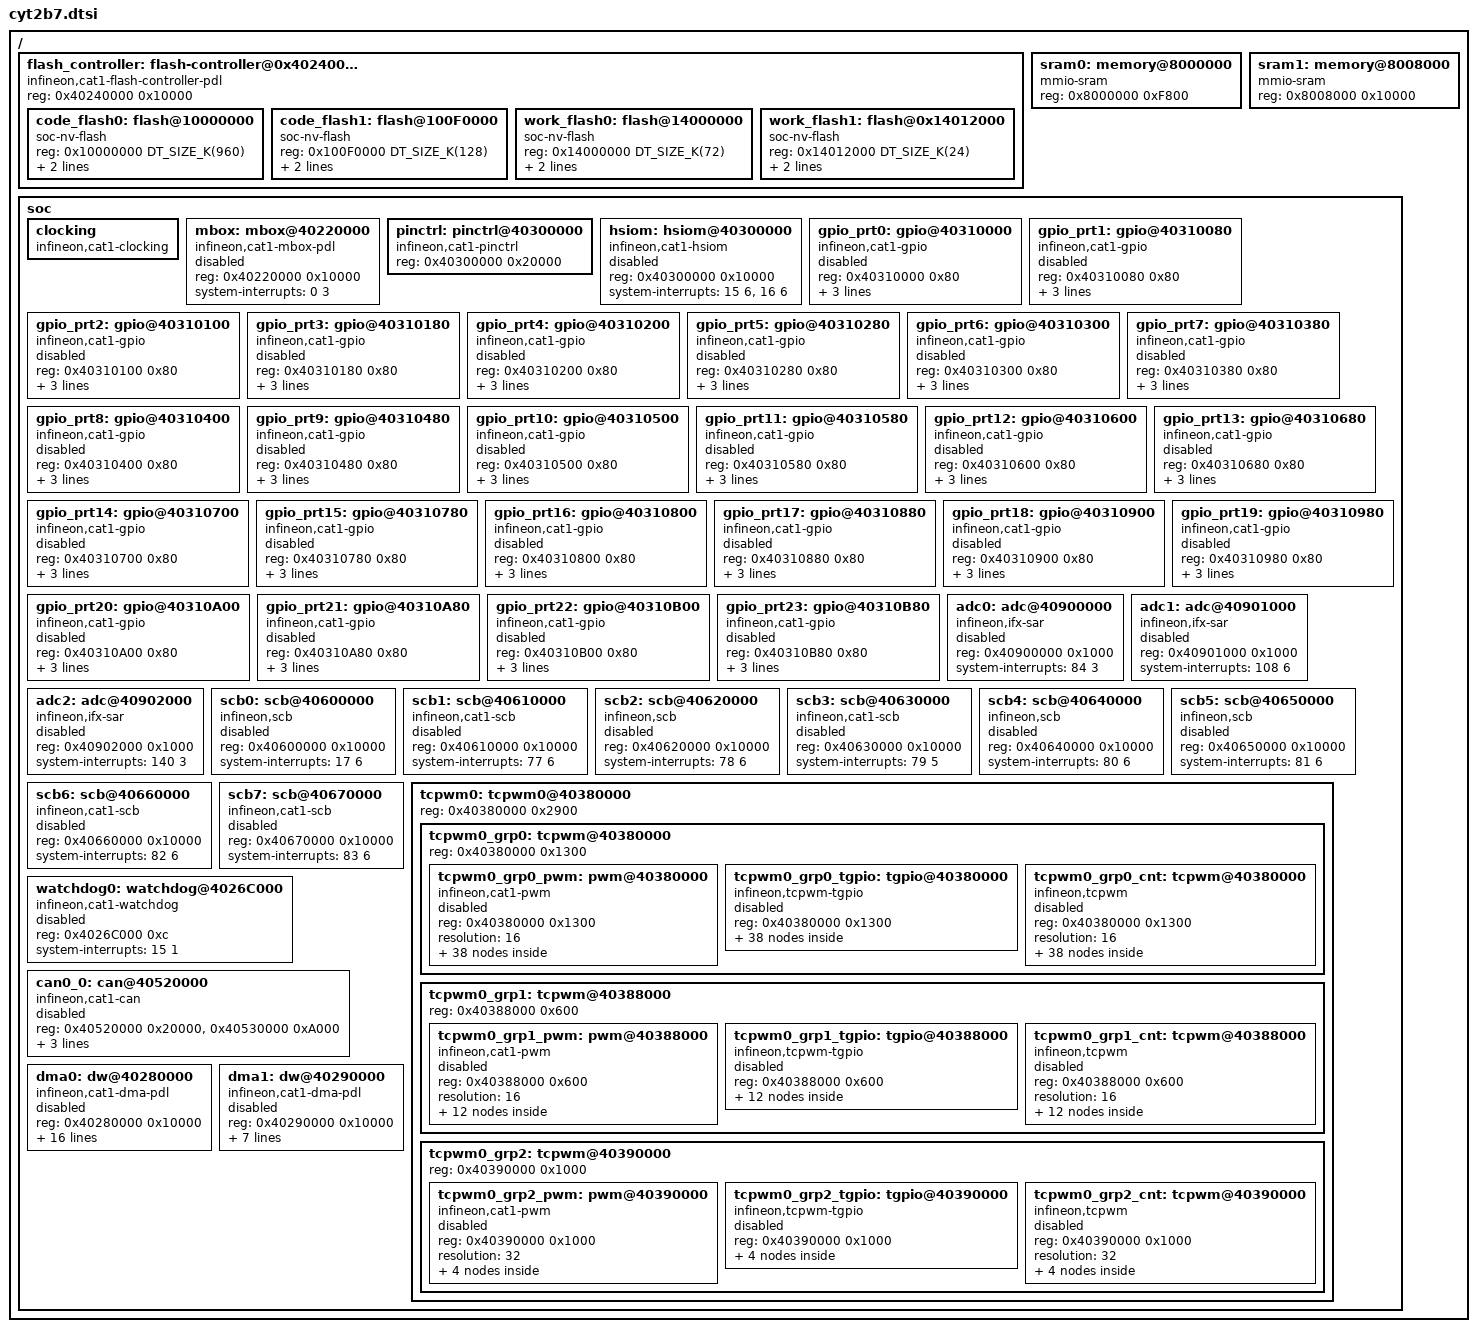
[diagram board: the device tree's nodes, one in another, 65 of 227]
/*
 * Copyright (c) 2025 Infineon Technologies AG,
 * or an affiliate of Infineon Technologies AG.
 *
 * SPDX-License-Identifier: Apache-2.0
 */

#include <mem.h>

/ {

	flash_controller: flash-controller@0x40240000 {
		compatible = "infineon,cat1-flash-controller-pdl";
		reg = <0x40240000 0x10000>;
		#address-cells = <1>;
		#size-cells = <1>;
		status = "okay";


		/* Code flash - Large sector (32KB Sectors) */
		code_flash0: flash@10000000 {
			compatible = "soc-nv-flash";
			reg = <0x10000000 DT_SIZE_K(960)>;
			write-block-size = <512>;
			erase-block-size = <32768>;
		};

		/* Code flash - Small sector (8KB Sectors) */
		code_flash1: flash@100F0000 {
			compatible = "soc-nv-flash";
			reg = <0x100F0000 DT_SIZE_K(128)>;
			write-block-size = <512>;
			erase-block-size = <8192>;
		};
		/* Work flash - Large sector (2KB Sectors) */
		work_flash0: flash@14000000 {
			compatible = "soc-nv-flash";
			reg = <0x14000000 DT_SIZE_K(72)>;
			write-block-size = <512>;
			erase-block-size = <2048>;
		};

		/* Work flash - Small sector (128B Sectors) */
		work_flash1: flash@0x14012000 {
			compatible = "soc-nv-flash";
			reg = <0x14012000 DT_SIZE_K(24)>;
			write-block-size = <64>;
			erase-block-size = <128>;
		};

	};

    sram0: memory@8000000 {
		compatible = "mmio-sram";
		reg = <0x8000000 0xF800>;
	};

	sram1: memory@8008000 {
		compatible = "mmio-sram";
		reg = <0x8008000 0x10000>;
	};


    soc {

		#address-cells = <1>;
		#size-cells = <1>;

		clocking: clocking {
			compatible = "infineon,cat1-clocking";
		};

		mbox: mbox@40220000 {
            compatible = "infineon,cat1-mbox-pdl";
            reg = <0x40220000 0x10000>;
            system-interrupts = <0 3>;
            #mbox-cells = <1>;
            status = "disabled";
        };

		pinctrl: pinctrl@40300000 {
			compatible = "infineon,cat1-pinctrl";
			reg = <0x40300000 0x20000>;
			#address-cells = <1>;
			#size-cells = <0>;
		};

		hsiom: hsiom@40300000 {
			compatible = "infineon,cat1-hsiom";
			reg = <0x40300000 0x10000>;
			system-interrupts = <15 6>, <16 6>;
			status = "disabled";
		};

        gpio_prt0: gpio@40310000 {
			compatible = "infineon,cat1-gpio";
			reg = <0x40310000 0x80>;
			system-interrupts = <21 6>;
			gpio-controller;
			ngpios = <8>;
			status = "disabled";
			#gpio-cells = <2>;
		};

        gpio_prt1: gpio@40310080 {
			compatible = "infineon,cat1-gpio";
			reg = <0x40310080 0x80>;
			system-interrupts = <22 6>;
			gpio-controller;
			ngpios = <8>;
			status = "disabled";
			#gpio-cells = <2>;
		};

        gpio_prt2: gpio@40310100 {
			compatible = "infineon,cat1-gpio";
			reg = <0x40310100 0x80>;
			system-interrupts = <23 6>;
			gpio-controller;
			ngpios = <8>;
			status = "disabled";
			#gpio-cells = <2>;
		};

        gpio_prt3: gpio@40310180 {
			compatible = "infineon,cat1-gpio";
			reg = <0x40310180 0x80>;
			system-interrupts = <24 6>;
			gpio-controller;
			ngpios = <8>;
			status = "disabled";
			#gpio-cells = <2>;
		};

        gpio_prt4: gpio@40310200 {
			compatible = "infineon,cat1-gpio";
			reg = <0x40310200 0x80>;
			system-interrupts = <25 6>;
			gpio-controller;
			ngpios = <8>;
			status = "disabled";
			#gpio-cells = <2>;
		};

        gpio_prt5: gpio@40310280 {
			compatible = "infineon,cat1-gpio";
			reg = <0x40310280 0x80>;
			system-interrupts = <26 6>;
			gpio-controller;
			ngpios = <8>;
			status = "disabled";
			#gpio-cells = <2>;
		};

        gpio_prt6: gpio@40310300 {
			compatible = "infineon,cat1-gpio";
			reg = <0x40310300 0x80>;
			system-interrupts = <27 6>;
			gpio-controller;
			ngpios = <8>;
			status = "disabled";
			#gpio-cells = <2>;
		};

        gpio_prt7: gpio@40310380 {
			compatible = "infineon,cat1-gpio";
			reg = <0x40310380 0x80>;
			system-interrupts = <28 6>;
			gpio-controller;
			ngpios = <8>;
			status = "disabled";
			#gpio-cells = <2>;
		};

        gpio_prt8: gpio@40310400 {
			compatible = "infineon,cat1-gpio";
			reg = <0x40310400 0x80>;
			system-interrupts = <29 6>;
			gpio-controller;
			ngpios = <8>;
			status = "disabled";
			#gpio-cells = <2>;
		};

        gpio_prt9: gpio@40310480 {
			compatible = "infineon,cat1-gpio";
			reg = <0x40310480 0x80>;
			system-interrupts = <30 6>;
			gpio-controller;
			ngpios = <8>;
			status = "disabled";
			#gpio-cells = <2>;
		};

        gpio_prt10: gpio@40310500 {
			compatible = "infineon,cat1-gpio";
			reg = <0x40310500 0x80>;
			system-interrupts = <31 6>;
			gpio-controller;
			ngpios = <8>;
			status = "disabled";
			#gpio-cells = <2>;
		};

        gpio_prt11: gpio@40310580 {
			compatible = "infineon,cat1-gpio";
			reg = <0x40310580 0x80>;
			system-interrupts = <32 6>;
			gpio-controller;
			ngpios = <8>;
			status = "disabled";
			#gpio-cells = <2>;
		};


        gpio_prt12: gpio@40310600 {
			compatible = "infineon,cat1-gpio";
			reg = <0x40310600 0x80>;
			system-interrupts = <33 6>;
			gpio-controller;
			ngpios = <8>;
			status = "disabled";
			#gpio-cells = <2>;
		};

        gpio_prt13: gpio@40310680 {
			compatible = "infineon,cat1-gpio";
			reg = <0x40310680 0x80>;
			system-interrupts = <34 6>;
			gpio-controller;
			ngpios = <8>;
			status = "disabled";
			#gpio-cells = <2>;
		};

        gpio_prt14: gpio@40310700 {
			compatible = "infineon,cat1-gpio";
			reg = <0x40310700 0x80>;
			system-interrupts = <35 6>;
			gpio-controller;
			ngpios = <8>;
			status = "disabled";
			#gpio-cells = <2>;
		};

        gpio_prt15: gpio@40310780 {
			compatible = "infineon,cat1-gpio";
			reg = <0x40310780 0x80>;
			system-interrupts = <36 6>;
			gpio-controller;
			ngpios = <8>;
			status = "disabled";
			#gpio-cells = <2>;
		};

        gpio_prt16: gpio@40310800 {
			compatible = "infineon,cat1-gpio";
			reg = <0x40310800 0x80>;
			system-interrupts = <37 6>;
			gpio-controller;
			ngpios = <8>;
			status = "disabled";
			#gpio-cells = <2>;
		};

        gpio_prt17: gpio@40310880 {
			compatible = "infineon,cat1-gpio";
			reg = <0x40310880 0x80>;
			system-interrupts = <38 6>;
			gpio-controller;
			ngpios = <8>;
			status = "disabled";
			#gpio-cells = <2>;
		};

        gpio_prt18: gpio@40310900 {
			compatible = "infineon,cat1-gpio";
			reg = <0x40310900 0x80>;
			system-interrupts = <39 6>;
			gpio-controller;
			ngpios = <8>;
			status = "disabled";
			#gpio-cells = <2>;
		};

        gpio_prt19: gpio@40310980 {
			compatible = "infineon,cat1-gpio";
			reg = <0x40310980 0x80>;
			system-interrupts = <40 6>;
			gpio-controller;
			ngpios = <8>;
			status = "disabled";
			#gpio-cells = <2>;
		};

        gpio_prt20: gpio@40310A00 {
			compatible = "infineon,cat1-gpio";
			reg = <0x40310A00 0x80>;
			system-interrupts = <41 6>;
			gpio-controller;
			ngpios = <8>;
			status = "disabled";
			#gpio-cells = <2>;
		};

        gpio_prt21: gpio@40310A80 {
			compatible = "infineon,cat1-gpio";
			reg = <0x40310A80 0x80>;
			system-interrupts = <42 6>;
			gpio-controller;
			ngpios = <8>;
			status = "disabled";
			#gpio-cells = <2>;
		};

        gpio_prt22: gpio@40310B00 {
			compatible = "infineon,cat1-gpio";
			reg = <0x40310B00 0x80>;
			system-interrupts = <43 6>;
			gpio-controller;
			ngpios = <8>;
			status = "disabled";
			#gpio-cells = <2>;
		};

        gpio_prt23: gpio@40310B80 {
			compatible = "infineon,cat1-gpio";
			reg = <0x40310B80 0x80>;
			system-interrupts = <44 6>;
			gpio-controller;
			ngpios = <8>;
			status = "disabled";
			#gpio-cells = <2>;
		};

		adc0: adc@40900000 {
			compatible = "infineon,ifx-sar";
			reg = <0x40900000 0x1000>;
			system-interrupts = <84 3>;
			status = "disabled";
			#io-channel-cells = <1>;

		};

		adc1: adc@40901000 {
			compatible = "infineon,ifx-sar";
			reg = <0x40901000 0x1000>;
			system-interrupts = <108 6>;
			status = "disabled";
			#io-channel-cells = <1>;
		};

		adc2: adc@40902000 {
			compatible = "infineon,ifx-sar";
			reg = <0x40902000 0x1000>;
			system-interrupts = <140 3>;
			status = "disabled";
			#io-channel-cells = <1>;
		};


		scb0: scb@40600000 {
			compatible = "infineon,scb";
			reg = <0x40600000 0x10000>;
			#address-cells = <1>;
			#size-cells = <0>;
			system-interrupts = <17 6>;
			status = "disabled";
		};

		scb1: scb@40610000 {
			compatible = "infineon,cat1-scb";
			reg = <0x40610000 0x10000>;
			#address-cells = <1>;
			#size-cells = <0>;
			system-interrupts = <77 6>;
			status = "disabled";
		};

		scb2: scb@40620000 {
			compatible = "infineon,scb";
			reg = <0x40620000 0x10000>;
			#address-cells = <1>;
			#size-cells = <0>;
			system-interrupts = <78 6>;
			status = "disabled";
		};

		scb3: scb@40630000 {
			compatible = "infineon,cat1-scb";
			reg = <0x40630000 0x10000>;
			#address-cells = <1>;
			#size-cells = <0>;
			system-interrupts = <79 5>;
			status = "disabled";
		};

		scb4: scb@40640000 {
			compatible = "infineon,scb";
			reg = <0x40640000 0x10000>;
			#address-cells = <1>;
			#size-cells = <0>;
			system-interrupts = <80 6>;
			status = "disabled";
		};

		scb5: scb@40650000 {
			compatible = "infineon,scb";
			reg = <0x40650000 0x10000>;
			#address-cells = <1>;
			#size-cells = <0>;
			system-interrupts = <81 6>;
			status = "disabled";
		};

		scb6: scb@40660000 {
			compatible = "infineon,cat1-scb";
			reg = <0x40660000 0x10000>;
			#address-cells = <1>;
			#size-cells = <0>;
			system-interrupts = <82 6>;
			status = "disabled";
		};

		scb7: scb@40670000 {
			compatible = "infineon,cat1-scb";
			reg = <0x40670000 0x10000>;
			#address-cells = <1>;
			#size-cells = <0>;
			system-interrupts = <83 6>;
			status = "disabled";
		};

		 tcpwm0: tcpwm0@40380000 {
			reg = <0x40380000 0x2900>;
			#address-cells = <1>;
			#size-cells = <1>;
			tcpwm0_grp0: tcpwm@40380000 {
				reg = <0x40380000 0x1300>;
				#address-cells = <1>;
				#size-cells = <1>;
				tcpwm0_grp0_pwm: pwm@40380000 {
					compatible = "infineon,cat1-pwm";
					reg = <0x40380000 0x1300>;
					#address-cells = <1>;
					#size-cells = <0>;
					#pwm-cells = <3>;
					resolution = <16>;
					status = "disabled";

					pwm_ch0_0: channel@0 {
						reg = <0x0>;
						system-interrupts = <274 4>;
						status = "disabled";
					};

					pwm_ch0_1: channel@1 {
						reg = <0x1>;
						system-interrupts = <275 4>;
						status = "disabled";
					};

					pwm_ch0_2: channel@2 {
						reg = <0x2>;
						system-interrupts = <276 4>;
						status = "disabled";
					};

					pwm_ch0_3: channel@3 {
						reg = <0x3>;
						system-interrupts = <277 4>;
						status = "disabled";
					};

					pwm_ch0_4: channel@4 {
						reg = <0x4>;
						system-interrupts = <278 4>;
						status = "disabled";
					};

					pwm_ch0_5: channel@5 {
						reg = <0x5>;
						system-interrupts = <279 4>;
						status = "disabled";
					};

					pwm_ch0_6: channel@6 {
						reg = <0x6>;
						system-interrupts = <280 4>;
						status = "disabled";
					};

					pwm_ch0_7: channel@7 {
						reg = <0x7>;
						system-interrupts = <281 4>;
						status = "disabled";
					};

					pwm_ch0_8: channel@8 {
						reg = <0x8>;
						system-interrupts = <282 4>;
						status = "disabled";
					};

					pwm_ch0_9: channel@9 {
						reg = <0x9>;
						system-interrupts = <283 4>;
						status = "disabled";
					};

					pwm_ch0_10: channel@a {
						reg = <0xa>;
						system-interrupts = <284 4>;
						status = "disabled";
					};

					pwm_ch0_11: channel@b {
						reg = <0xb>;
						system-interrupts = <285 4>;
						status = "disabled";
					};

					pwm_ch0_12: channel@c {
						reg = <0xc>;
						system-interrupts = <286 4>;
						status = "disabled";
					};

					pwm_ch0_13: channel@d {
						reg = <0xd>;
						system-interrupts = <287 4>;
						status = "disabled";
					};

					pwm_ch0_14: channel@e {
						reg = <0xe>;
						system-interrupts = <288 4>;
						status = "disabled";
					};

					pwm_ch0_15: channel@f {
						reg = <0xf>;
						system-interrupts = <289 4>;
						status = "disabled";
					};

					pwm_ch0_16: channel@10 {
						reg = <0x10>;
						system-interrupts = <290 4>;
						status = "disabled";
					};

					pwm_ch0_17: channel@11 {
						reg = <0x11>;
						system-interrupts = <291 4>;
						status = "disabled";
					};

					pwm_ch0_18: channel@12 {
						reg = <0x12>;
						system-interrupts = <292 4>;
						status = "disabled";
					};

					pwm_ch0_19: channel@13 {
						reg = <0x13>;
						system-interrupts = <293 4>;
						status = "disabled";
					};

					pwm_ch0_20: channel@14 {
						reg = <0x14>;
						system-interrupts = <294 4>;
						status = "disabled";
					};

					pwm_ch0_21: channel@15 {
						reg = <0x15>;
						system-interrupts = <295 4>;
						status = "disabled";
					};

					pwm_ch0_22: channel@16 {
						reg = <0x16>;
						system-interrupts = <296 4>;
						status = "disabled";
					};

					pwm_ch0_23: channel@17 {
						reg = <0x17>;
						system-interrupts = <297 4>;
						status = "disabled";
					};

					pwm_ch0_24: channel@18 {
						reg = <0x18>;
						system-interrupts = <298 4>;
						status = "disabled";
					};

					pwm_ch0_25: channel@19 {
						reg = <0x19>;
						system-interrupts = <299 4>;
						status = "disabled";
					};

					pwm_ch0_26: channel@1a {
						reg = <0x1a>;
						system-interrupts = <300 4>;
						status = "disabled";
					};

					pwm_ch0_27: channel@1b {
						reg = <0x1b>;
						system-interrupts = <301 4>;
						status = "disabled";
					};

					pwm_ch0_28: channel@1c {
						reg = <0x1c>;
						system-interrupts = <302 4>;
						status = "disabled";
					};

					pwm_ch0_29: channel@1d {
						reg = <0x1d>;
						system-interrupts = <303 4>;
						status = "disabled";
					};

					pwm_ch0_30: channel@1e {
						reg = <0x1e>;
						system-interrupts = <304 4>;
						status = "disabled";
					};

					pwm_ch0_31: channel@1f {
						reg = <0x1f>;
						system-interrupts = <305 4>;
						status = "disabled";
					};

					pwm_ch0_32: channel@20 {
						reg = <0x20>;
						system-interrupts = <306 4>;
						status = "disabled";
					};

					pwm_ch0_33: channel@21 {
						reg = <0x21>;
						system-interrupts = <307 4>;
						status = "disabled";
					};

					pwm_ch0_34: channel@22 {
						reg = <0x22>;
						system-interrupts = <308 4>;
						status = "disabled";
					};

					pwm_ch0_35: channel@23 {
						reg = <0x23>;
						system-interrupts = <309 4>;
						status = "disabled";
					};

					pwm_ch0_36: channel@24 {
						reg = <0x24>;
						system-interrupts = <310 4>;
						status = "disabled";
					};

					pwm_ch0_37: channel@25 {
						reg = <0x25>;
						system-interrupts = <311 4>;
						status = "disabled";
					};
				};

				tcpwm0_grp0_tgpio: tgpio@40380000 {
					compatible = "infineon,tcpwm-tgpio";
					reg = <0x40380000 0x1300>;
					#address-cells = <1>;
					#size-cells = <0>;
					status = "disabled";

					tgpio_ch0_0: channel@0 {
						reg = <0x0>;
						system-interrupts = <274 4>;
						status = "disabled";
					};

					tgpio_ch0_1: channel@1 {
						reg = <0x1>;
						system-interrupts = <275 4>;
						status = "disabled";
					};

					tgpio_ch0_2: channel@2 {
						reg = <0x2>;
						system-interrupts = <276 4>;
						status = "disabled";
					};

					tgpio_ch0_3: channel@3 {
						reg = <0x3>;
						system-interrupts = <277 4>;
						status = "disabled";
					};

					tgpio_ch0_4: channel@4 {
						reg = <0x4>;
						system-interrupts = <278 4>;
						status = "disabled";
					};

					 tgpio_ch0_5: channel@5 {
						 reg = <0x5>;
						 system-interrupts = <279 4>;
						 status = "disabled";
					 };

					 tgpio_ch0_6: channel@6 {
						 reg = <0x6>;
						 system-interrupts = <280 4>;
						 status = "disabled";
					 };

					 tgpio_ch0_7: channel@7 {
						 reg = <0x7>;
						 system-interrupts = <281 4>;
						 status = "disabled";
					 };

					 tgpio_ch0_8: channel@8 {
						 reg = <0x8>;
						 system-interrupts = <282 4>;
						 status = "disabled";
					 };

					 tgpio_ch0_9: channel@9 {
						 reg = <0x9>;
						 system-interrupts = <283 4>;
						 status = "disabled";
					 };

					 tgpio_ch0_10: channel@a {
						 reg = <0xa>;
						 system-interrupts = <284 4>;
						 status = "disabled";
					 };

					 tgpio_ch0_11: channel@b {
						 reg = <0xb>;
						 system-interrupts = <285 4>;
						 status = "disabled";
					 };

					 tgpio_ch0_12: channel@c {
						 reg = <0xc>;
						 system-interrupts = <286 4>;
						 status = "disabled";
					 };

					 tgpio_ch0_13: channel@d {
						 reg = <0xd>;
						 system-interrupts = <287 4>;
						 status = "disabled";
					 };

					 tgpio_ch0_14: channel@e {
						 reg = <0xe>;
						 system-interrupts = <288 4>;
						 status = "disabled";
					 };

					 tgpio_ch0_15: channel@f {
						 reg = <0xf>;
						 system-interrupts = <289 4>;
						 status = "disabled";
					 };

					 tgpio_ch0_16: channel@10 {
						 reg = <0x10>;
						 system-interrupts = <290 4>;
						 status = "disabled";
					 };

					 tgpio_ch0_17: channel@11 {
						 reg = <0x11>;
						 system-interrupts = <291 4>;
						 status = "disabled";
					 };

					 tgpio_ch0_18: channel@12 {
						 reg = <0x12>;
						 system-interrupts = <292 4>;
						 status = "disabled";
					 };

					 tgpio_ch0_19: channel@13 {
						 reg = <0x13>;
						 system-interrupts = <293 4>;
						 status = "disabled";
					 };

					 tgpio_ch0_20: channel@14 {
						 reg = <0x14>;
						 system-interrupts = <294 4>;
						 status = "disabled";
					 };

					 tgpio_ch0_21: channel@15 {
						 reg = <0x15>;
						 system-interrupts = <295 4>;
						 status = "disabled";
					 };

					 tgpio_ch0_22: channel@16 {
						 reg = <0x16>;
						 system-interrupts = <296 4>;
						 status = "disabled";
					 };

					 tgpio_ch0_23: channel@17 {
						 reg = <0x17>;
						 system-interrupts = <297 4>;
						 status = "disabled";
					 };

					 tgpio_ch0_24: channel@18 {
						 reg = <0x18>;
						 system-interrupts = <298 4>;
						 status = "disabled";
					 };

					 tgpio_ch0_25: channel@19 {
						 reg = <0x19>;
						 system-interrupts = <299 4>;
						 status = "disabled";
					 };

					 tgpio_ch0_26: channel@1a {
						 reg = <0x1a>;
						 system-interrupts = <300 4>;
						 status = "disabled";
					 };

					 tgpio_ch0_27: channel@1b {
						 reg = <0x1b>;
						 system-interrupts = <301 4>;
						 status = "disabled";
					 };
					tgpio_ch0_28: channel@1c {
						reg = <0x1c>;
						system-interrupts = <302 4>;
						status = "disabled";
					};

					tgpio_ch0_29: channel@1d {
						reg = <0x1d>;
						system-interrupts = <303 4>;
						status = "disabled";
					};

					tgpio_ch0_30: channel@1e {
						reg = <0x1e>;
						system-interrupts = <304 4>;
						status = "disabled";
					};

					tgpio_ch0_31: channel@1f {
						reg = <0x1f>;
						system-interrupts = <305 4>;
						status = "disabled";
					};

					tgpio_ch0_32: channel@20 {
						reg = <0x20>;
						system-interrupts = <306 4>;
						status = "disabled";
					};

					tgpio_ch0_33: channel@21 {
						reg = <0x21>;
						system-interrupts = <307 4>;
						status = "disabled";
					};

					tgpio_ch0_34: channel@22 {
						reg = <0x22>;
						system-interrupts = <308 4>;
						status = "disabled";
					};

					tgpio_ch0_35: channel@23 {
						reg = <0x23>;
						system-interrupts = <309 4>;
						status = "disabled";
					};

					tgpio_ch0_36: channel@24 {
						reg = <0x24>;
						system-interrupts = <310 4>;
						status = "disabled";
					};

					tgpio_ch0_37: channel@25 {
						reg = <0x25>;
						system-interrupts = <311 4>;
						status = "disabled";
					};
				};

				tcpwm0_grp0_cnt: tcpwm@40380000 {
					compatible = "infineon,tcpwm";
					reg = <0x40380000 0x1300>;
					#address-cells = <1>;
					#size-cells = <1>;
					resolution = <16>;
					status = "disabled";

					counter0_0: counter@40380000 {
						compatible = "infineon,tcpwm-counter";
						reg = <0x40380000 0x80>;
						system-interrupts = <274 4>;
						status = "disabled";
					};

					counter0_1: counter@40380080 {
						compatible = "infineon,tcpwm-counter";
						reg = <0x40380080 0x80>;
						system-interrupts = <275 4>;
						status = "disabled";
					};

					counter0_2: counter@40380100 {
						compatible = "infineon,tcpwm-counter";
						reg = <0x40380100 0x80>;
						system-interrupts = <276 4>;
						status = "disabled";
					};

					counter0_3: counter@40380180 {
						compatible = "infineon,tcpwm-counter";
						reg = <0x40380180 0x80>;
						system-interrupts = <277 4>;
						status = "disabled";
					};

					counter0_4: counter@40380200 {
						compatible = "infineon,tcpwm-counter";
						reg = <0x40380200 0x80>;
						system-interrupts = <278 4>;
						status = "disabled";
					};

					counter0_5: counter@40380280 {
						compatible = "infineon,tcpwm-counter";
						reg = <0x40380280 0x80>;
						system-interrupts = <279 4>;
						status = "disabled";
					};

					counter0_6: counter@40380300 {
						compatible = "infineon,tcpwm-counter";
						reg = <0x40380300 0x80>;
						system-interrupts = <280 4>;
						status = "disabled";
					};

					counter0_7: counter@40380380 {
						compatible = "infineon,tcpwm-counter";
						reg = <0x40380380 0x80>;
						system-interrupts = <281 4>;
						status = "disabled";
					};

					counter0_8: counter@40380400 {
						compatible = "infineon,tcpwm-counter";
						reg = <0x40380400 0x80>;
						system-interrupts = <282 4>;
						status = "disabled";
					};

					counter0_9: counter@40380480 {
						compatible = "infineon,tcpwm-counter";
						reg = <0x40380480 0x80>;
						system-interrupts = <283 4>;
						status = "disabled";
					};

					counter0_10: counter@40380500 {
						compatible = "infineon,tcpwm-counter";
						reg = <0x40380500 0x80>;
						system-interrupts = <284 4>;
						status = "disabled";
					};

					counter0_11: counter@40380580 {
						compatible = "infineon,tcpwm-counter";
						reg = <0x40380580 0x80>;
						system-interrupts = <285 4>;
						status = "disabled";
					};

					counter0_12: counter@40380600 {
						compatible = "infineon,tcpwm-counter";
						reg = <0x40380600 0x80>;
						system-interrupts = <286 4>;
						status = "disabled";
					};

					counter0_13: counter@40380680 {
						compatible = "infineon,tcpwm-counter";
						reg = <0x40380680 0x80>;
						system-interrupts = <287 4>;
						status = "disabled";
					};

					counter0_14: counter@40380700 {
						compatible = "infineon,tcpwm-counter";
						reg = <0x40380700 0x80>;
						system-interrupts = <288 4>;
						status = "disabled";
					};

					counter0_15: counter@40380780 {
						compatible = "infineon,tcpwm-counter";
						reg = <0x40380780 0x80>;
						system-interrupts = <289 4>;
						status = "disabled";
					};

					counter0_16: counter@40380800 {
						compatible = "infineon,tcpwm-counter";
						reg = <0x40380800 0x80>;
						system-interrupts = <290 4>;
						status = "disabled";
					};

					counter0_17: counter@40380880 {
						compatible = "infineon,tcpwm-counter";
						reg = <0x40380880 0x80>;
						system-interrupts = <291 4>;
						status = "disabled";
					};

					counter0_18: counter@40380900 {
						compatible = "infineon,tcpwm-counter";
						reg = <0x40380900 0x80>;
						system-interrupts = <292 4>;
						status = "disabled";
					};

					counter0_19: counter@40380980 {
						compatible = "infineon,tcpwm-counter";
						reg = <0x40380980 0x80>;
						system-interrupts = <293 4>;
						status = "disabled";
					};

					counter0_20: counter@40380a00 {
						compatible = "infineon,tcpwm-counter";
						reg = <0x40380a00 0x80>;
						system-interrupts = <294 4>;
						status = "disabled";
					};

					counter0_21: counter@40380a80 {
						compatible = "infineon,tcpwm-counter";
						reg = <0x40380a80 0x80>;
						system-interrupts = <295 4>;
						status = "disabled";
					};

					counter0_22: counter@40380b00 {
						compatible = "infineon,tcpwm-counter";
						reg = <0x40380b00 0x80>;
						system-interrupts = <296 4>;
						status = "disabled";
					};

					counter0_23: counter@40380b80 {
						compatible = "infineon,tcpwm-counter";
						reg = <0x40380b80 0x80>;
						system-interrupts = <297 4>;
						status = "disabled";
					};

					counter0_24: counter@40380c00 {
						compatible = "infineon,tcpwm-counter";
						reg = <0x40380c00 0x80>;
						system-interrupts = <298 4>;
						status = "disabled";
					};

					counter0_25: counter@40380c80 {
						compatible = "infineon,tcpwm-counter";
						reg = <0x40380c80 0x80>;
						system-interrupts = <299 4>;
						status = "disabled";
					};

					counter0_26: counter@40380d00 {
						compatible = "infineon,tcpwm-counter";
						reg = <0x40380d00 0x80>;
						system-interrupts = <300 4>;
						status = "disabled";
					};

					counter0_27: counter@40380d80 {
						compatible = "infineon,tcpwm-counter";
						reg = <0x40380d80 0x80>;
						system-interrupts = <301 4>;
						status = "disabled";
					};

					counter0_28: counter@40380e00 {
						compatible = "infineon,tcpwm-counter";
						reg = <0x40380e00 0x80>;
						system-interrupts = <302 4>;
						status = "disabled";
					};

					counter0_29: counter@40380e80 {
						compatible = "infineon,tcpwm-counter";
						reg = <0x40380e80 0x80>;
						system-interrupts = <303 4>;
						status = "disabled";
					};

					counter0_30: counter@40380f00 {
						compatible = "infineon,tcpwm-counter";
						reg = <0x40380f00 0x80>;
						system-interrupts = <304 4>;
						status = "disabled";
					};

					counter0_31: counter@40380f80 {
						compatible = "infineon,tcpwm-counter";
						reg = <0x40380f80 0x80>;
						system-interrupts = <305 4>;
						status = "disabled";
					};

					counter0_32: counter@40381000 {
						compatible = "infineon,tcpwm-counter";
						reg = <0x40381000 0x80>;
						system-interrupts = <306 4>;
						status = "disabled";
					};

					counter0_33: counter@40381080 {
						compatible = "infineon,tcpwm-counter";
						reg = <0x40381080 0x80>;
						system-interrupts = <307 4>;
						status = "disabled";
					};

					counter0_34: counter@40381100 {
						compatible = "infineon,tcpwm-counter";
						reg = <0x40381100 0x80>;
						system-interrupts = <308 4>;
						status = "disabled";
					};

					counter0_35: counter@40381180 {
						compatible = "infineon,tcpwm-counter";
						reg = <0x40381180 0x80>;
						system-interrupts = <309 4>;
						status = "disabled";
					};

					counter0_36: counter@40381200 {
						compatible = "infineon,tcpwm-counter";
						reg = <0x40381200 0x80>;
						system-interrupts = <310 4>;
						status = "disabled";
					};

					counter0_37: counter@40381280 {
						compatible = "infineon,tcpwm-counter";
						reg = <0x40381280 0x80>;
						system-interrupts = <311 4>;
						status = "disabled";
					};
				};
			};

			tcpwm0_grp1: tcpwm@40388000 {
				reg = <0x40388000 0x600>;
				#address-cells = <1>;
				#size-cells = <1>;
				tcpwm0_grp1_pwm: pwm@40388000 {
					compatible = "infineon,cat1-pwm";
					reg = <0x40388000 0x600>;
					#address-cells = <1>;
					#size-cells = <0>;
					#pwm-cells = <3>;
					resolution = <16>;
					status = "disabled";

					pwm_ch1_0: channel@0 {
						reg = <0x0>;
						system-interrupts = <337 4>;
						status = "disabled";
					};

					pwm_ch1_1: channel@1 {
						reg = <0x1>;
						system-interrupts = <338 4>;
						status = "disabled";
					};

					pwm_ch1_2: channel@2 {
						reg = <0x2>;
						system-interrupts = <339 4>;
						status = "disabled";
					};

					pwm_ch1_3: channel@3 {
						reg = <0x3>;
						system-interrupts = <340 4>;
						status = "disabled";
					};

					pwm_ch1_4: channel@4 {
						reg = <0x4>;
						system-interrupts = <341 4>;
						status = "disabled";
					};

					pwm_ch1_5: channel@5 {
						reg = <0x5>;
						system-interrupts = <342 4>;
						status = "disabled";
					};

					pwm_ch1_6: channel@6 {
						reg = <0x6>;
						system-interrupts = <343 4>;
						status = "disabled";
					};

					pwm_ch1_7: channel@7 {
						reg = <0x7>;
						system-interrupts = <344 4>;
						status = "disabled";
					};

					pwm_ch1_8: channel@8 {
						reg = <0x8>;
						system-interrupts = <345 4>;
						status = "disabled";
					};

					pwm_ch1_9: channel@9 {
						reg = <0x9>;
						system-interrupts = <346 4>;
						status = "disabled";
					};

					pwm_ch1_10: channel@a {
						reg = <0xa>;
						system-interrupts = <347 4>;
						status = "disabled";
					};

					pwm_ch1_11: channel@b {
						reg = <0xb>;
						system-interrupts = <348 4>;
						status = "disabled";
					};
				};

				tcpwm0_grp1_tgpio: tgpio@40388000 {
					compatible = "infineon,tcpwm-tgpio";
					reg = <0x40388000 0x600>;
					#address-cells = <1>;
					#size-cells = <0>;
					status = "disabled";

					tgpio_ch1_0: channel@0 {
						reg = <0x0>;
						system-interrupts = <337 4>;
						status = "disabled";
					};

					tgpio_ch1_1: channel@1 {
						reg = <0x1>;
						system-interrupts = <338 4>;
						status = "disabled";
					};

					tgpio_ch1_2: channel@2 {
						reg = <0x2>;
						system-interrupts = <339 4>;
						status = "disabled";
					};

					tgpio_ch1_3: channel@3 {
						reg = <0x3>;
						system-interrupts = <340 4>;
						status = "disabled";
					};

					tgpio_ch1_4: channel@4 {
						reg = <0x4>;
						system-interrupts = <341 4>;
						status = "disabled";
					};

					tgpio_ch1_5: channel@5 {
						reg = <0x5>;
						system-interrupts = <342 4>;
						status = "disabled";
					};

					tgpio_ch1_6: channel@6 {
						reg = <0x6>;
						system-interrupts = <343 4>;
						status = "disabled";
					};

					tgpio_ch1_7: channel@7 {
						reg = <0x7>;
						system-interrupts = <344 4>;
						status = "disabled";
					};

					tgpio_ch1_8: channel@8 {
						reg = <0x8>;
						system-interrupts = <345 4>;
						status = "disabled";
					};

					tgpio_ch1_9: channel@9 {
						reg = <0x9>;
						system-interrupts = <346 4>;
						status = "disabled";
					};

					tgpio_ch1_10: channel@a {
						reg = <0xa>;
						system-interrupts = <347 4>;
						status = "disabled";
					};

					tgpio_ch1_11: channel@b {
						reg = <0xb>;
						system-interrupts = <348 4>;
						status = "disabled";
					};
				};
			tcpwm0_grp1_cnt: tcpwm@40388000 {
					compatible = "infineon,tcpwm";
					reg = <0x40388000 0x600>;
					#address-cells = <1>;
					#size-cells = <1>;
					resolution = <16>;
					status = "disabled";

					counter1_0: counter@40388000 {
						compatible = "infineon,tcpwm-counter";
						reg = <0x40388000 0x80>;
						system-interrupts = <337 4>;
						status = "disabled";
					};

					counter1_1: counter@40388080 {
						compatible = "infineon,tcpwm-counter";
						reg = <0x40388080 0x80>;
						system-interrupts = <338 4>;
						status = "disabled";
					};

					counter1_2: counter@40388100 {
						compatible = "infineon,tcpwm-counter";
						reg = <0x40388100 0x80>;
						system-interrupts = <339 4>;
						status = "disabled";
					};

					counter1_3: counter@40388180 {
						compatible = "infineon,tcpwm-counter";
						reg = <0x40388180 0x80>;
						system-interrupts = <340 4>;
						status = "disabled";
					};

					counter1_4: counter@40388200 {
						compatible = "infineon,tcpwm-counter";
						reg = <0x40388200 0x80>;
						system-interrupts = <341 4>;
						status = "disabled";
					};

					counter1_5: counter@40388280 {
						compatible = "infineon,tcpwm-counter";
						reg = <0x40388280 0x80>;
						system-interrupts = <342 4>;
						status = "disabled";
					};

					counter1_6: counter@40388300 {
						compatible = "infineon,tcpwm-counter";
						reg = <0x40388300 0x80>;
						system-interrupts = <343 4>;
						status = "disabled";
					};

					counter1_7: counter@40388380 {
						compatible = "infineon,tcpwm-counter";
						reg = <0x40388380 0x80>;
						system-interrupts = <344 4>;
						status = "disabled";
					};

					counter1_8: counter@40388400 {
						compatible = "infineon,tcpwm-counter";
						reg = <0x40388400 0x80>;
						system-interrupts = <345 4>;
						status = "disabled";
					};

					counter1_9: counter@40388480 {
						compatible = "infineon,tcpwm-counter";
						reg = <0x40388480 0x80>;
						system-interrupts = <346 4>;
						status = "disabled";
					};

					counter1_10: counter@40388500 {
						compatible = "infineon,tcpwm-counter";
						reg = <0x40388500 0x80>;
						system-interrupts = <347 4>;
						status = "disabled";
					};

					counter1_11: counter@40388580 {
						compatible = "infineon,tcpwm-counter";
						reg = <0x40388580 0x80>;
						system-interrupts = <348 4>;
						status = "disabled";
					};
				};
			};

			tcpwm0_grp2: tcpwm@40390000 {
				reg = <0x40390000 0x1000>;
				#address-cells = <1>;
				#size-cells = <1>;
				tcpwm0_grp2_pwm: pwm@40390000 {
					compatible = "infineon,cat1-pwm";
					reg = <0x40390000 0x1000>;
					#address-cells = <1>;
					#size-cells = <0>;
					#pwm-cells = <3>;
					resolution = <32>;
					status = "disabled";

					pwm_ch2_0: channel@0 {
						reg = <0x0>;
						system-interrupts = <349 4>;
						status = "disabled";
					};

					pwm_ch2_1: channel@1 {
						reg = <0x1>;
						system-interrupts = <350 4>;
						status = "disabled";
					};

					pwm_ch2_2: channel@2 {
						reg = <0x2>;
						system-interrupts = <351 4>;
						status = "disabled";
					};

					pwm_ch2_3: channel@3 {
						reg = <0x3>;
						system-interrupts = <352 4>;
						status = "disabled";
					};
				};


				tcpwm0_grp2_tgpio: tgpio@40390000 {
					compatible = "infineon,tcpwm-tgpio";
					reg = <0x40390000 0x1000>;
					#address-cells = <1>;
					#size-cells = <0>;
					status = "disabled";

					tgpio_ch2_0: channel@0 {
						reg = <0x0>;
						system-interrupts = <349 4>;
						status = "disabled";
					};

					tgpio_ch2_1: channel@1 {
						reg = <0x1>;
						system-interrupts = <350 4>;
						status = "disabled";
					};

					tgpio_ch2_2: channel@2 {
						reg = <0x2>;
						system-interrupts = <351 4>;
						status = "disabled";
					};

					tgpio_ch2_3: channel@3 {
						reg = <0x3>;
						system-interrupts = <352 4>;
						status = "disabled";
					};
				};

				tcpwm0_grp2_cnt: tcpwm@40390000 {
					compatible = "infineon,tcpwm";
					reg = <0x40390000 0x1000>;
					#address-cells = <1>;
					#size-cells = <1>;
					resolution = <32>;
					status = "disabled";

					counter2_0: counter@40390000 {
						compatible = "infineon,tcpwm-counter";
						reg = <0x40390000 0x80>;
						system-interrupts = <349 4>;
						status = "disabled";
					};

					counter2_1: counter@40390080 {
						compatible = "infineon,tcpwm-counter";
						reg = <0x40390080 0x80>;
						system-interrupts = <350 4>;
						status = "disabled";
					};

					counter2_2: counter@40390100 {
						compatible = "infineon,tcpwm-counter";
						reg = <0x40390100 0x80>;
						system-interrupts = <351 4>;
						status = "disabled";
					};

					counter2_3: counter@40390180 {
						compatible = "infineon,tcpwm-counter";
						reg = <0x40390180 0x80>;
						system-interrupts = <352 4>;
						status = "disabled";
					};
				};
			};
		};



		watchdog0: watchdog@4026C000 {
			compatible = "infineon,cat1-watchdog";
			reg = <0x4026C000 0xc>;
			system-interrupts = <15 1>;
			status = "disabled";
		};

		can0_0: can@40520000 {
            compatible = "infineon,cat1-can";
            reg = <0x40520000 0x20000>, <0x40530000 0xA000>;
            reg-names = "m_can", "message_ram";
            system-interrupts = <57 2>, <60 2>;
            clocks = <&clk_hf2>;
            bosch,mram-cfg = <0x0 28 8 3 3 1 3 3>;
            status = "disabled";
        };

		dma0: dw@40280000 {
			#dma-cells = <1>;
			compatible = "infineon,cat1-dma-pdl";
			reg = <0x40280000 0x10000>;
			dma-channels = <89>;
			interrupts = <152 6>, /* CH0 */
					    <153 6>, /* CH1 */
					    <154 6>, /* CH2 */
					    <155 6>, /* CH3 */
					    <156 6>, /* CH4 */
					    <157 6>, /* CH5 */
					    <158 6>, /* CH6 */
					    <159 6>, /* CH7 */
					    <160 6>, /* CH8 */
					    <161 6>, /* CH9 */
					    <162 6>, /* CH10 */
					    <163 6>, /* CH11 */
					    <164 6>, /* CH12 */
					    <165 6>, /* CH13 */
					    <166 6>, /* CH14 */
					    <167 6>, /* CH15 */
					    <168 6>, /* CH16 */
					    <169 6>, /* CH17 */
					    <170 6>, /* CH18 */
					    <171 6>, /* CH19 */
					    <172 6>, /* CH20 */
					    <173 6>, /* CH21 */
					    <174 6>, /* CH22 */
					    <175 6>, /* CH23 */
					    <176 6>, /* CH24 */
					    <177 6>, /* CH25 */
					    <178 6>, /* CH26 */
					    <179 6>, /* CH27 */
					    <180 6>, /* CH28 */
					    <181 6>, /* CH29 */
					    <182 6>, /* CH30 */
					    <183 6>, /* CH31 */
					    <184 6>, /* CH32 */
					    <185 6>, /* CH33 */
					    <186 6>, /* CH34 */
					    <187 6>, /* CH35 */
					    <188 6>, /* CH36 */
					    <189 6>, /* CH37 */
					    <190 6>, /* CH38 */
					    <191 6>, /* CH39 */
					    <192 6>, /* CH40 */
					    <193 6>, /* CH41 */
					    <194 6>, /* CH42 */
					    <195 6>, /* CH43 */
					    <196 6>, /* CH44 */
					    <197 6>, /* CH45 */
					    <198 6>, /* CH46 */
					    <199 6>, /* CH47 */
					    <200 6>, /* CH48 */
					    <201 6>, /* CH49 */
					    <202 6>, /* CH50 */
					    <203 6>, /* CH51 */
					    <204 6>, /* CH52 */
					    <205 6>, /* CH53 */
					    <206 6>, /* CH54 */
					    <207 6>, /* CH55 */
					    <208 6>, /* CH56 */
					    <209 6>, /* CH57 */
					    <210 6>, /* CH58 */
					    <211 6>, /* CH59 */
					    <212 6>, /* CH60 */
					    <213 6>, /* CH61 */
					    <214 6>, /* CH62 */
					    <215 6>, /* CH63 */
					    <216 6>, /* CH64 */
					    <217 6>, /* CH65 */
					    <218 6>, /* CH66 */
					    <219 6>, /* CH67 */
					    <220 6>, /* CH68 */
					    <221 6>, /* CH69 */
					    <222 6>, /* CH70 */
					    <223 6>, /* CH71 */
					    <224 6>, /* CH72 */
					    <225 6>, /* CH73 */
					    <226 6>, /* CH74 */
					    <227 6>, /* CH75 */
					    <228 6>, /* CH76 */
					    <229 6>, /* CH77 */
					    <230 6>, /* CH78 */
					    <231 6>, /* CH79 */
					    <232 6>, /* CH80 */
					    <233 6>, /* CH81 */
					    <234 6>, /* CH82 */
					    <235 6>, /* CH83 */
					    <236 6>, /* CH84 */
					    <237 6>, /* CH85 */
					    <238 6>, /* CH86 */
					    <239 6>, /* CH87 */
					    <240 6>; /* CH88 */
			status = "disabled";
		};

		dma1: dw@40290000 {
			#dma-cells = <1>;
			compatible = "infineon,cat1-dma-pdl";
			reg = <0x40290000 0x10000>;
			dma-channels = <33>;
			interrupts = <241 6>, /* CH0 */
					    <242 6>, /* CH1 */
					    <243 6>, /* CH2 */
					    <244 6>, /* CH3 */
					    <245 6>, /* CH4 */
					    <246 6>, /* CH5 */
					    <247 6>, /* CH6 */
					    <248 6>, /* CH7 */
					    <249 6>, /* CH8 */
					    <250 6>, /* CH9 */
					    <251 6>, /* CH10 */
					    <252 6>, /* CH11 */
					    <253 6>, /* CH12 */
					    <254 6>, /* CH13 */
					    <255 6>, /* CH14 */
					    <256 6>, /* CH15 */
					    <257 6>, /* CH16 */
					    <258 6>, /* CH17 */
					    <259 6>, /* CH18 */
					    <260 6>, /* CH19 */
					    <261 6>, /* CH20 */
					    <262 6>, /* CH21 */
					    <263 6>, /* CH22 */
					    <264 6>, /* CH23 */
					    <265 6>, /* CH24 */
					    <266 6>, /* CH25 */
					    <267 6>, /* CH26 */
					    <268 6>, /* CH27 */
					    <269 6>, /* CH28 */
					    <270 6>, /* CH29 */
					    <271 6>, /* CH30 */
					    <272 6>, /* CH31 */
					    <273 6>; /* CH32 */
			status = "disabled";
		};







    };

};
